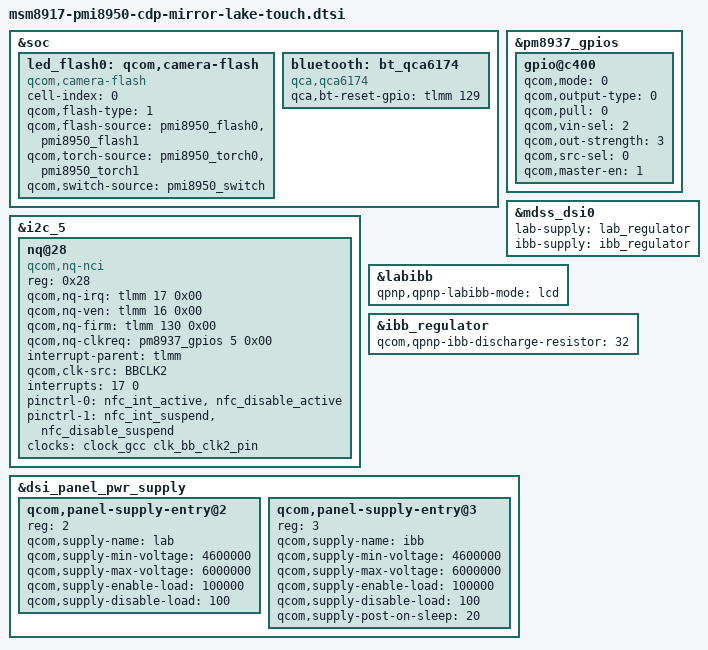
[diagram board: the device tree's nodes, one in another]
/*
 * Copyright (c) 2017, The Linux Foundation. All rights reserved.
 *
 * This program is free software; you can redistribute it and/or modify
 * it under the terms of the GNU General Public License version 2 and
 * only version 2 as published by the Free Software Foundation.
 *
 * This program is distributed in the hope that it will be useful,
 * but WITHOUT ANY WARRANTY; without even the implied warranty of
 * MERCHANTABILITY or FITNESS FOR A PARTICULAR PURPOSE.  See the
 * GNU General Public License for more details.
 */

#include "msm-pmi8950.dtsi"
#include "msm8917-cdp-mirror-lake-touch.dtsi"
#include "msm8917-audio-cdp.dtsi"

&soc {
	led_flash0: qcom,camera-flash {
		cell-index = <0>;
		compatible = "qcom,camera-flash";
		qcom,flash-type = <1>;
		qcom,flash-source = <&pmi8950_flash0 &pmi8950_flash1>;
		qcom,torch-source = <&pmi8950_torch0 &pmi8950_torch1>;
		qcom,switch-source = <&pmi8950_switch>;
	};

	bluetooth: bt_qca6174 {
		compatible = "qca,qca6174";
		qca,bt-reset-gpio = <&tlmm 129 0>; /* BT_EN */
	};
};

&pm8937_gpios {
	gpio@c400 {
		qcom,mode = <0>;
		qcom,output-type = <0>;
		qcom,pull = <0>;
		qcom,vin-sel = <2>;
		qcom,out-strength = <3>;
		qcom,src-sel = <0>;
		qcom,master-en = <1>;
		status = "okay";
	};
};

&i2c_5 { /* BLSP2 QUP1 */
	nq@28 {
		compatible = "qcom,nq-nci";
		reg = <0x28>;
		qcom,nq-irq = <&tlmm 17 0x00>;
		qcom,nq-ven = <&tlmm 16 0x00>;
		qcom,nq-firm = <&tlmm 130 0x00>;
		qcom,nq-clkreq = <&pm8937_gpios 5 0x00>;
		interrupt-parent = <&tlmm>;
		qcom,clk-src = "BBCLK2";
		interrupts = <17 0>;
		interrupt-names = "nfc_irq";
		pinctrl-names = "nfc_active", "nfc_suspend";
		pinctrl-0 = <&nfc_int_active &nfc_disable_active>;
		pinctrl-1 = <&nfc_int_suspend &nfc_disable_suspend>;
		clocks = <&clock_gcc clk_bb_clk2_pin>;
		clock-names = "ref_clk";
	};
};

&mdss_dsi0 {
	lab-supply = <&lab_regulator>;
	ibb-supply = <&ibb_regulator>;
};

&labibb {
	status = "ok";
	qpnp,qpnp-labibb-mode = "lcd";
};

&ibb_regulator {
	qcom,qpnp-ibb-discharge-resistor = <32>;
};

&dsi_panel_pwr_supply {
	qcom,panel-supply-entry@2 {
		reg = <2>;
		qcom,supply-name = "lab";
		qcom,supply-min-voltage = <4600000>;
		qcom,supply-max-voltage = <6000000>;
		qcom,supply-enable-load = <100000>;
		qcom,supply-disable-load = <100>;
	};

	qcom,panel-supply-entry@3 {
		reg = <3>;
		qcom,supply-name = "ibb";
		qcom,supply-min-voltage = <4600000>;
		qcom,supply-max-voltage = <6000000>;
		qcom,supply-enable-load = <100000>;
		qcom,supply-disable-load = <100>;
		qcom,supply-post-on-sleep = <20>;
	};
};
